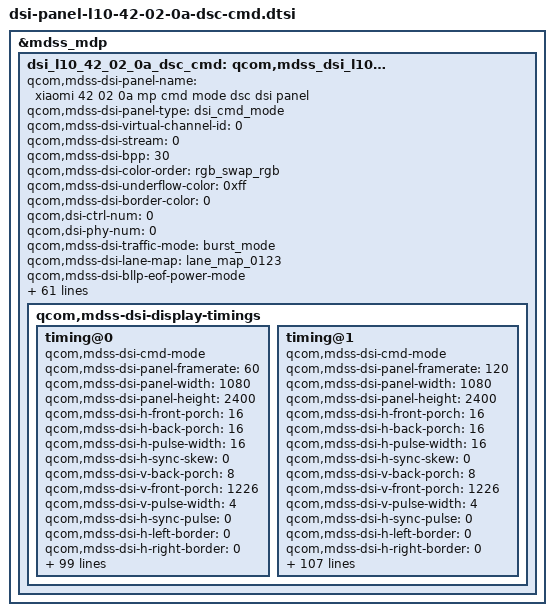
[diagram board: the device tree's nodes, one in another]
&mdss_mdp {
	dsi_l10_42_02_0a_dsc_cmd: qcom,mdss_dsi_l10_42_02_0a_dsc_cmd {
		qcom,mdss-dsi-panel-name = "xiaomi 42 02 0a mp cmd mode dsc dsi panel";
		qcom,mdss-dsi-panel-type = "dsi_cmd_mode";
		qcom,mdss-dsi-virtual-channel-id = <0>;
		qcom,mdss-dsi-stream = <0>;
		qcom,mdss-dsi-bpp = <30>;
		qcom,mdss-dsi-color-order = "rgb_swap_rgb";
		qcom,mdss-dsi-underflow-color = <0xff>;
		qcom,mdss-dsi-border-color = <0>;

		qcom,dsi-ctrl-num = <0>;
		qcom,dsi-phy-num = <0>;

		qcom,mdss-dsi-traffic-mode = "burst_mode";
		qcom,mdss-dsi-lane-map = "lane_map_0123";
		qcom,mdss-dsi-bllp-eof-power-mode;
		qcom,mdss-dsi-bllp-power-mode;
		qcom,mdss-dsi-lane-0-state;
		qcom,mdss-dsi-lane-1-state;
		qcom,mdss-dsi-lane-2-state;
		qcom,mdss-dsi-lane-3-state;
		qcom,mdss-dsi-dma-trigger = "trigger_sw";
		qcom,mdss-dsi-mdp-trigger = "none";
		qcom,mdss-dsi-reset-sequence =  <1 11>, <0 1>, <1 11>;
		qcom,mdss-pan-physical-width-dimension = <695>;
		qcom,mdss-pan-physical-height-dimension = <1545>;
		qcom,mdss-dsi-te-pin-select = <1>;
		qcom,mdss-dsi-wr-mem-start = <0x2c>;
		qcom,mdss-dsi-wr-mem-continue = <0x3c>;
		qcom,mdss-dsi-te-dcs-command = <1>;
		qcom,mdss-dsi-te-check-enable;
		qcom,mdss-dsi-te-using-te-pin;
		qcom,mdss-dsi-tx-eot-append;
		qcom,mdss-dsi-lp11-init;

		qcom,mdss-dsi-bl-inverted-dbv;
		qcom,bl-update-flag = "delay_until_first_frame";
		qcom,mdss-dsi-panel-mode-switch;

		qcom,mdss-dsi-panel-hdr-enabled;
		qcom,mdss-dsi-panel-hdr-color-primaries = <14500 15500 32000 17000 15500 30000 8000 3000>;
		qcom,mdss-dsi-panel-peak-brightness = <4200000>;
		qcom,mdss-dsi-panel-blackness-level = <3230>;
		qcom,mdss-dsi-dma-schedule-line = <1>;
		qcom,mdss-dsi-dma-schedule-window = <10>;

		qcom,mdss-dsi-display-timings {
			/* 60 Hz */
			timing@0{
				qcom,mdss-dsi-cmd-mode;
				qcom,mdss-dsi-panel-framerate = <60>;
				qcom,mdss-dsi-panel-width = <1080>;
				qcom,mdss-dsi-panel-height = <2400>;
				qcom,mdss-dsi-h-front-porch = <16>;
				qcom,mdss-dsi-h-back-porch = <16>;
				qcom,mdss-dsi-h-pulse-width = <16>;
				qcom,mdss-dsi-h-sync-skew = <0>;
				qcom,mdss-dsi-v-back-porch = <8>;
				qcom,mdss-dsi-v-front-porch = <1226>;
				qcom,mdss-dsi-v-pulse-width = <4>;
				qcom,mdss-dsi-h-sync-pulse = <0>;
				qcom,mdss-dsi-h-left-border = <0>;
				qcom,mdss-dsi-h-right-border = <0>;
				qcom,mdss-dsi-v-top-border = <0>;
				qcom,mdss-dsi-v-bottom-border = <0>;
				qcom,mdss-dsi-panel-clockrate = <1100000000>;
				qcom,mdss-dsi-panel-jitter = <0x5 0x1>;
				qcom,mdss-mdp-transfer-time-us = <6800>;
				qcom,mdss-dsi-on-command = [
					/* enter aod with no black */
					39 00 00 00 00 00 05 FF AA 55 A5 80
					15 00 00 00 00 00 02 6F 61
					15 00 00 00 00 00 02 F3 80
					/* VESA ON */
					15 00 00 00 00 00 02 90 01
					/* VESA Edition */
					39 00 00 00 00 00 13 91
						AB 28 00 0C C2 00 03 1C 01 7E 00 0F 08 BB 04 3D
						10 F0
					15 00 00 00 00 00 02 03 01
					15 00 00 00 00 00 02 2C 00
					/* TE ON */
					15 00 00 00 00 00 02 35 00
					/* BACKLIGHT ON */
					15 00 00 00 00 00 02 53 20
					39 00 00 00 00 00 05 51 00 00 00 00
					/* CASET/RASET */
					39 00 00 00 00 00 05 2A 00 00 04 37
					39 00 00 00 00 00 05 2B 00 00 09 5F
					/* 60 Hz */
					15 00 00 00 00 00 02 2F 01
					15 00 00 00 00 00 02 26 01
					/* OSC calibration */
					39 00 00 00 00 00 06 F0 55 AA 52 08 01
					39 00 00 00 00 00 08 C3 9B 01 94 D0 22 02 00
					/* round on */
					39 00 00 00 00 00 06 F0 55 AA 52 08 07
					39 00 00 00 00 00 03 C0 05 02
					/*ESD Error flag  Active high*/
					39 00 00 40 00 00 06 F0 55 AA 52 08 00
					39 00 00 40 00 00 02 6F 05
					39 00 00 00 00 00 02 BE 08
					/* VBP & VFP */
					39 00 00 00 00 00 05 3B 00 14 00 1C
					/* fix cts 120hz failed */
					39 00 00 00 00 00 06 F0 55 AA 52 08 00
					39 00 00 00 00 00 03 BA 01 B1
					39 00 00 00 00 00 02 6F 08
					39 00 00 00 00 00 03 BA 01 B1
					39 00 00 00 00 00 03 BB 01 B1
					/* Sleep Out */
					05 00 00 00 50 00 02 11 00
					/* Display On */
					05 00 00 00 00 00 02 29 00
				];
				qcom,mdss-dsi-off-command = [
					05 00 00 00 00 00 02 28 00
					05 00 00 00 64 00 02 10 00
				];
				qcom,mdss-dsi-on-command-state = "dsi_lp_mode";
				qcom,mdss-dsi-off-command-state = "dsi_lp_mode";

				qcom,mdss-dsi-timing-switch-command = [
					/* 60 Hz */
					39 00 00 40 00 00 02 2F 01
					39 00 00 00 00 00 02 26 01
				];
				qcom,mdss-dsi-timing-switch-command-state = "dsi_hs_mode";
				qcom,mdss-dsi-timing-switch-command-update = <0x26 1 1>;

				qcom,mdss-dsi-nolp-command = [
					39 00 00 00 00 00 06 F0 55 AA 52 08 00
					39 00 00 40 00 00 02 B2 18
					39 00 00 00 00 00 02 65 00
					39 00 00 00 00 00 02 38 00
				];
				qcom,mdss-dsi-nolp-command-state = "dsi_lp_mode";

				qcom,compression-mode = "dsc";
				qcom,mdss-dsc-version = <0x11>;
				qcom,mdss-dsc-scr-version = <0x0>;
				qcom,mdss-dsc-slice-height = <12>;
				qcom,mdss-dsc-slice-width = <1080>;
				qcom,mdss-dsc-slice-per-pkt = <1>;
				qcom,mdss-dsc-bit-per-component = <10>;
				qcom,mdss-dsc-bit-per-pixel = <8>;
				qcom,mdss-dsc-block-prediction-enable;
			};

			/* 120Hz */
			timing@1 {
				qcom,mdss-dsi-cmd-mode;
				qcom,mdss-dsi-panel-framerate = <120>;
				qcom,mdss-dsi-panel-width = <1080>;
				qcom,mdss-dsi-panel-height = <2400>;
				qcom,mdss-dsi-h-front-porch = <16>;
				qcom,mdss-dsi-h-back-porch = <16>;
				qcom,mdss-dsi-h-pulse-width = <16>;
				qcom,mdss-dsi-h-sync-skew = <0>;
				qcom,mdss-dsi-v-back-porch = <8>;
				qcom,mdss-dsi-v-front-porch = <1226>;
				qcom,mdss-dsi-v-pulse-width = <4>;
				qcom,mdss-dsi-h-sync-pulse = <0>;
				qcom,mdss-dsi-h-left-border = <0>;
				qcom,mdss-dsi-h-right-border = <0>;
				qcom,mdss-dsi-v-top-border = <0>;
				qcom,mdss-dsi-v-bottom-border = <0>;
				qcom,mdss-dsi-panel-clockrate = <1100000000>;
				qcom,mdss-dsi-panel-jitter = <0x5 0x1>;
				qcom,mdss-mdp-transfer-time-us = <6800>;
				qcom,mdss-dsi-on-command = [
					/* enter aod with no black */
					39 00 00 00 00 00 05 FF AA 55 A5 80
					15 00 00 00 00 00 02 6F 61
					15 00 00 00 00 00 02 F3 80
					/* VESA ON */
					15 00 00 00 00 00 02 90 01
					/* VESA Edition */
					39 00 00 00 00 00 13 91
						AB 28 00 0C C2 00 03 1C 01 7E 00 0F 08 BB 04 3D
						10 F0
					15 00 00 00 00 00 02 03 01
					15 00 00 00 00 00 02 2C 00
					/* TE ON */
					15 00 00 00 00 00 02 35 00
					/* BACKLIGHT ON */
					15 00 00 00 00 00 02 53 20
					39 00 00 00 00 00 05 51 00 00 00 00
					/* CASET/RASET */
					39 00 00 00 00 00 05 2A 00 00 04 37
					39 00 00 00 00 00 05 2B 00 00 09 5F
					/* 120 Hz */
					39 00 00 00 00 00 06 F0 55 AA 52 08 00
					15 00 00 00 00 00 02 6F 09
					15 00 00 00 00 00 02 C0 20
					15 00 00 00 00 00 02 2F 02
					/* OSC calibration */
					39 00 00 00 00 00 06 F0 55 AA 52 08 01
					39 00 00 00 00 00 08 C3 9B 01 94 D0 22 02 00
					/* round on */
					39 00 00 00 00 00 06 F0 55 AA 52 08 07
					39 00 00 00 00 00 03 C0 05 02
					/*ESD Error flag  Active high*/
					39 00 00 40 00 00 06 F0 55 AA 52 08 00
					39 00 00 40 00 00 02 6F 05
					39 00 00 00 00 00 02 BE 08
					/* fix cts 120hz failed */
					39 00 00 00 00 00 06 F0 55 AA 52 08 00
					39 00 00 00 00 00 03 BA 01 B1
					39 00 00 00 00 00 02 6F 08
					39 00 00 00 00 00 03 BA 01 B1
					39 00 00 00 00 00 03 BB 01 B1
					/* VBP & VFP */
					39 00 00 00 00 00 05 3B 00 14 00 1C
					/* Sleep Out */
					05 00 00 00 50 00 02 11 00
					/* Display On */
					05 00 00 00 00 00 02 29 00
				];

				qcom,mdss-dsi-off-command = [
					05 00 00 00 00 00 02 28 00
					05 00 00 00 64 00 02 10 00
				];
				qcom,mdss-dsi-on-command-state = "dsi_lp_mode";
				qcom,mdss-dsi-off-command-state = "dsi_lp_mode";

				qcom,mdss-dsi-timing-switch-command = [
					/* 120 Hz */
					39 00 00 00 00 00 02 2F 02
					39 00 00 40 00 00 06 F0 55 AA 52 08 00
					39 00 00 40 00 00 02 6F 09
					39 00 00 40 00 00 02 C0 20
					39 00 00 40 00 00 06 F0 55 AA 52 08 02
					39 00 00 40 00 00 02 CC 30
					39 00 00 00 0A 00 02 CE 01
					/*120 Hz  cmd_2*/
					39 00 00 00 00 00 06 F0 55 AA 52 08 02
					39 00 00 00 00 00 02 CC 00
				];
				qcom,mdss-dsi-timing-switch-command-update = <0xC0 3 1>;
				qcom,mdss-dsi-timing-switch-command-state = "dsi_hs_mode";

				qcom,mdss-dsi-nolp-command = [
					39 00 00 00 00 00 06 F0 55 AA 52 08 00
					39 00 00 40 00 00 02 B2 18
					39 00 00 00 00 00 02 65 00
					39 00 00 40 22 00 02 38 00
					/* 120 Hz */
					39 00 00 40 00 00 06 F0 55 AA 52 08 00
					39 00 00 40 00 00 02 6F 09
					39 00 00 40 00 00 02 C0 20
					39 00 00 00 00 00 02 2F 02
				];
				qcom,mdss-dsi-nolp-command-state = "dsi_lp_mode";

				qcom,compression-mode = "dsc";
				qcom,mdss-dsc-version = <0x11>;
				qcom,mdss-dsc-scr-version = <0x0>;
				qcom,mdss-dsc-slice-height = <12>;
				qcom,mdss-dsc-slice-width = <1080>;
				qcom,mdss-dsc-slice-per-pkt = <1>;
				qcom,mdss-dsc-bit-per-component = <10>;
				qcom,mdss-dsc-bit-per-pixel = <8>;
				qcom,mdss-dsc-block-prediction-enable;
			};

		};
	};
};

&dsi_l10_42_02_0a_dsc_cmd {
	mi,panel-id = <0x004C3130 0x00420200>;
	mi,hbm-51-ctl-flag;
	mi,hbm-bl-min-level = <1>;
	mi,hbm-bl-max-level = <2047>;
	mi,panel-on-dimming-delay = <120>;

	/* IRQF_ONESHOT | IRQF_TRIGGER_HIGH */
	mi,esd-err-irq-gpio = <&tlmm 116 0x2004>;
	qcom,esd-check-enabled;
	qcom,esd-aod-check-enabled;
	qcom,mdss-dsi-panel-status-check-mode = "reg_read";
	qcom,mdss-dsi-panel-status-offset-command = [
		39 00 00 00 00 00 05 FF AA 55 A5 81
		15 00 00 00 00 00 02 6F 0F];
	qcom,mdss-dsi-panel-status-command = [
		06 00 00 01 00 00 01 FA
		06 00 00 01 00 00 01 91];
	qcom,mdss-dsi-panel-status-read-length = <1 18>;
	qcom,mdss-dsi-panel-max-error-count = <3>;
	qcom,mdss-dsi-panel-status-value = <0x00>,
			<0xAB 0x28 0x00 0x0C 0xC2 0x00 0x03 0x1C 0x01 0x7E 0x00 0x0F 0x08 0xBB 0x04 0x3D 0x10 0xF0>;
	qcom,mdss-dsi-panel-status-command-state = "dsi_lp_mode";
	qcom,mdss-dsi-panel-status-offset-command-state = "dsi_lp_mode";


	mi,ddic-round-corner-enabled;

	mi,flat-update-flag;
	mi,flat-need-sync-te;

	mi,max-brightness-clone = <4095>;
	mi,mdss-dsi-fac-bl-max-level = <2047>;
	mi,mdss-fac-brightness-max-level = <2047>;
	mi,doze-hbm-dbv-level = <252>;
	mi,doze-lbm-dbv-level = <20>;
	mi,thermal-dimming-flag;

	mi,panel-hbm-backlight-threshold = <2047>;
	mi,panel-count-hbm-by-backlight-flag;

	qcom,mdss-dsi-display-timings {
		timing@0{ /* 60 hz */
			/*<flat on gamma, flat off gamma>*/
			mi,mdss-flat-status-control-gamma-cfg = <0x04 0x01>;

			mi,mdss-dsi-dimmingon-command = [15 00 00 00 00 00 02 53 28];
			mi,mdss-dsi-dimmingon-command-state = "dsi_hs_mode";
			mi,mdss-dsi-dimmingoff-command = [15 00 00 00 00 00 02 53 20];
			mi,mdss-dsi-dimmingoff-command-state = "dsi_hs_mode";

			mi,mdss-dsi-switch-page-command = [
				/* switch page, last byte is page config */
				39 00 00 00 00 00 06 F0 55 AA 52 08 00
			];
			/* <mipi_address  update_index  update_length> */
			mi,mdss-dsi-switch-page-command-update = <0xF0 0 5>;
			mi,mdss-dsi-switch-page-command-state = "dsi_lp_mode";

			mi,mdss-dsi-flat-mode-read-pre-command = [
				39 00 00 00 00 00 06 F0 55 AA 52 08 00
				39 00 00 00 00 00 02 6F 3F
			];
			mi,mdss-dsi-flat-mode-read-pre-command-state = "dsi_lp_mode";

			mi,mdss-dsi-flat-mode-on-command = [
				/* 60 Hz */
				39 00 00 00 00 00 02 2F 01
				39 00 00 60 00 00 02 26 04
				39 00 00 60 00 00 06 F0 55 AA 52 08 08
				39 00 00 60 00 00 02 6F 07
				39 00 00 20 00 00 05 B9 00 00 00 00
			];
			/* <mipi_address  update_index  update_length> */
			mi,mdss-dsi-flat-mode-on-command-update = <0xB9 4 4>;
			mi,mdss-dsi-flat-mode-on-command-state = "dsi_lp_mode";

			mi,mdss-dsi-flat-mode-off-read-pre-command = [
				39 00 00 00 00 00 06 F0 55 AA 52 08 00
				39 00 00 00 00 00 02 6F 48
			];
			mi,mdss-dsi-flat-mode-off-read-pre-command-state = "dsi_lp_mode";

			mi,mdss-dsi-flat-mode-off-command = [
				/* 60 Hz */
				39 00 00 00 00 00 02 2F 01
				39 00 00 60 00 00 02 26 01
				39 00 00 60 00 00 06 F0 55 AA 52 08 08
				39 00 00 60 00 00 02 6F 07
				39 00 00 20 00 00 05 B9 00 00 00 00
			];
			/* <mipi_address  update_index  update_length> */
			mi,mdss-dsi-flat-mode-off-command-update = <0xB9 4 4>;
			mi,mdss-dsi-flat-mode-off-command-state = "dsi_lp_mode";

			mi,mdss-dsi-hbm-on-command = [
				39 00 00 00 00 00 05 51 0F FF 00 00];
			mi,mdss-dsi-hbm-on-command-state = "dsi_lp_mode";
			mi,mdss-dsi-hbm-off-command = [
				39 00 00 00 00 00 05 51 07 FF 00 00];
			mi,mdss-dsi-hbm-off-command-state = "dsi_lp_mode";

			mi,mdss-dsi-doze-hbm-command = [
				/* 60 Hz */
				39 00 00 60 00 00 02 2F 01
				39 00 00 60 00 00 02 26 01
				39 00 00 60 00 00 06 F0 55 AA 52 08 00
				39 00 00 60 00 00 02 B2 08
				39 00 00 60 00 00 05 51 00 00 0F FF
				39 00 00 60 00 00 01 39
				39 00 00 20 00 00 02 65 01
			];
			mi,mdss-dsi-doze-hbm-command-state = "dsi_lp_mode";

			mi,mdss-dsi-doze-lbm-command = [
				/* 60 Hz */
				39 00 00 60 00 00 02 2F 01
				39 00 00 60 00 00 02 26 01
				39 00 00 60 00 00 06 F0 55 AA 52 08 00
				39 00 00 60 00 00 02 B2 08
				39 00 00 60 00 00 05 51 00 00 01 55
				39 00 00 60 00 00 01 39
				39 00 00 20 00 00 02 65 01
			];
			mi,mdss-dsi-doze-lbm-command-state = "dsi_lp_mode";

			mi,mdss-dsi-doze-hbm-nolp-command = [
				39 00 00 00 00 00 06 F0 55 AA 52 08 00
				39 00 00 40 00 00 02 B2 18
				39 00 00 40 00 00 05 51 00 00 0F FF
				39 00 00 00 00 00 02 65 00
				39 00 00 00 07 00 01 38
			];
			mi,mdss-dsi-doze-hbm-nolp-command-state = "dsi_lp_mode";

			mi,mdss-dsi-doze-lbm-nolp-command = [
				39 00 00 00 00 00 06 F0 55 AA 52 08 00
				39 00 00 40 00 00 02 B2 18
				39 00 00 40 00 00 05 51 00 00 0F FF
				39 00 00 00 00 00 02 65 00
				39 00 00 00 07 00 01 38
			];
			mi,mdss-dsi-doze-lbm-nolp-command-state = "dsi_lp_mode";

			mi,mdss-dsi-doze-to-off-command = [
				39 00 00 40 00 00 06 F0 55 AA 52 08 01
				39 00 00 00 00 00 02 CE 0C
				39 00 00 40 00 00 02 28 00
				39 00 00 00 AA 00 02 10 00
			];
			mi,mdss-dsi-doze-to-off-command-state = "dsi_lp_mode";

			mi,mdss-dsi-round-corner-on-command = [
				/* Page 07 */
				39 00 00 00 00 00 06 F0 55 AA 52 08 07
				/* Round on */
				39 00 00 00 00 00 03 C0 05 02
			];
			mi,mdss-dsi-round-corner-on-command-state = "dsi_lp_mode";
			mi,mdss-dsi-round-corner-off-command = [
				/* Page 07 */
				39 00 00 00 00 00 06 F0 55 AA 52 08 07
				/* Round off */
				39 00 00 00 00 00 03 C0 00 02
			];
			mi,mdss-dsi-round-corner-off-command-state = "dsi_lp_mode";
		};

		timing@1{ /* 120 hz */
			/*<flat on gamma, flat off gamma>*/
			mi,mdss-flat-status-control-gamma-cfg = <0x60 0x20>;

			mi,mdss-dsi-dimmingon-command = [15 00 00 00 00 00 02 53 28];
			mi,mdss-dsi-dimmingon-command-state = "dsi_hs_mode";
			mi,mdss-dsi-dimmingoff-command = [15 00 00 00 00 00 02 53 20];
			mi,mdss-dsi-dimmingoff-command-state = "dsi_hs_mode";

			mi,mdss-dsi-hbm-on-command = [
				39 00 00 00 00 00 05 51 0F FF 00 00];
			mi,mdss-dsi-hbm-on-command-state = "dsi_lp_mode";
			mi,mdss-dsi-hbm-off-command = [
				39 00 00 00 00 00 05 51 07 FF 00 00];
			mi,mdss-dsi-hbm-off-command-state = "dsi_lp_mode";

			mi,mdss-dsi-switch-page-command = [
				/* switch page, last byte is page config */
				39 00 00 00 00 00 06 F0 55 AA 52 08 00
			];
			/* <mipi_address  update_index  update_length> */
			mi,mdss-dsi-switch-page-command-update = <0xF0 0 5>;
			mi,mdss-dsi-switch-page-command-state = "dsi_lp_mode";

			mi,mdss-dsi-flat-mode-read-pre-command = [
				39 00 00 00 00 00 06 F0 55 AA 52 08 00
				39 00 00 00 00 00 02 6F 3F
			];
			mi,mdss-dsi-flat-mode-read-pre-command-state = "dsi_lp_mode";

			mi,mdss-dsi-flat-mode-on-command = [
				/* 120 Hz gir cmd_1,need sync te*/
				39 00 00 60 00 00 02 2F 02
				39 00 00 60 00 00 06 F0 55 AA 52 08 00
				39 00 00 60 00 00 02 6F 09
				39 00 00 60 00 00 02 C0 60
				39 00 00 60 00 00 06 F0 55 AA 52 08 02
				39 00 00 60 00 00 02 CC 30
				39 00 00 60 00 00 02 CE 01
				39 00 00 60 00 00 06 F0 55 AA 52 08 08
				39 00 00 60 00 00 02 6F 07
				39 00 00 20 08 00 05 B9 00 00 00 00
			];
			/* <mipi_address  update_index  update_length> */
			mi,mdss-dsi-flat-mode-on-command-update = <0xB9 9 4>;

			mi,mdss-dsi-flat-mode-on-sec-command = [
				/* 120 Hz gir cmd_2*/
				39 00 00 00 00 00 06 F0 55 AA 52 08 02
				39 00 00 00 00 00 02 CC 00
			];
			mi,mdss-dsi-flat-mode-on-command-state = "dsi_hs_mode";
			mi,mdss-dsi-flat-mode-on-sec-command-state = "dsi_lp_mode";

			mi,mdss-dsi-flat-mode-off-read-pre-command = [
				39 00 00 00 00 00 06 F0 55 AA 52 08 00
				39 00 00 00 00 00 02 6F 48
			];
			mi,mdss-dsi-flat-mode-off-read-pre-command-state = "dsi_lp_mode";

			mi,mdss-dsi-flat-mode-off-command = [
				/* 120 Hz gir cmd_1,need sync te*/
				39 00 00 60 00 00 02 2F 02
				39 00 00 60 00 00 06 F0 55 AA 52 08 00
				39 00 00 60 00 00 02 6F 09
				39 00 00 60 00 00 02 C0 20
				39 00 00 60 00 00 06 F0 55 AA 52 08 02
				39 00 00 60 00 00 02 CC 30
				39 00 00 60 00 00 02 CE 01
				39 00 00 60 00 00 06 F0 55 AA 52 08 08
				39 00 00 60 00 00 02 6F 07
				39 00 00 20 08 00 05 B9 00 00 00 00
			];
			/* <mipi_address  update_index  update_length> */
			mi,mdss-dsi-flat-mode-off-command-update = <0xB9 9 4>;

			mi,mdss-dsi-flat-mode-off-sec-command = [
				/* 120 Hz gir cmd_2*/
				39 00 00 00 00 00 06 F0 55 AA 52 08 02
				39 00 00 00 00 00 02 CC 00
			];
			mi,mdss-dsi-flat-mode-off-command-state = "dsi_hs_mode";
			mi,mdss-dsi-flat-mode-off-sec-command-state = "dsi_lp_mode";

			mi,mdss-dsi-doze-hbm-command = [
				/* 60 Hz */
				39 00 00 60 00 00 02 2F 01
				39 00 00 60 00 00 02 26 01
				39 00 00 60 00 00 06 F0 55 AA 52 08 00
				39 00 00 60 00 00 02 B2 08
				39 00 00 60 00 00 05 51 00 00 0F FF
				39 00 00 60 00 00 01 39
				39 00 00 20 00 00 02 65 01
			];
			mi,mdss-dsi-doze-hbm-command-state = "dsi_lp_mode";

			mi,mdss-dsi-doze-lbm-command = [
				/* 60 Hz */
				39 00 00 60 00 00 02 2F 01
				39 00 00 60 00 00 02 26 01
				39 00 00 60 00 00 06 F0 55 AA 52 08 00
				39 00 00 60 00 00 02 B2 08
				39 00 00 60 00 00 05 51 00 00 01 55
				39 00 00 60 00 00 01 39
				39 00 00 20 00 00 02 65 01
			];
			mi,mdss-dsi-doze-lbm-command-state = "dsi_lp_mode";

			mi,mdss-dsi-doze-hbm-nolp-command = [
				39 00 00 00 00 00 06 F0 55 AA 52 08 00
				39 00 00 40 00 00 02 B2 18
				39 00 00 00 00 00 05 51 00 00 0F FF
				39 00 00 00 00 00 02 65 00
				39 00 00 00 07 00 01 38
				/* 120 Hz */
				39 00 00 00 00 00 06 F0 55 AA 52 08 00
				39 00 00 40 00 00 02 6F 09
				39 00 00 40 00 00 02 C0 20
				39 00 00 00 00 00 02 2F 02
			];
			mi,mdss-dsi-doze-hbm-nolp-command-state = "dsi_lp_mode";

			mi,mdss-dsi-doze-lbm-nolp-command = [
				39 00 00 00 00 00 06 F0 55 AA 52 08 00
				39 00 00 40 00 00 02 B2 18
				39 00 00 00 00 00 05 51 00 00 0F FF
				39 00 00 00 00 00 02 65 00
				39 00 00 00 07 00 01 38
				/* 120 Hz */
				39 00 00 00 00 00 06 F0 55 AA 52 08 00
				39 00 00 40 00 00 02 6F 09
				39 00 00 40 00 00 02 C0 20
				39 00 00 00 00 00 02 2F 02
			];
			mi,mdss-dsi-doze-lbm-nolp-command-state = "dsi_lp_mode";

			mi,mdss-dsi-doze-to-off-command = [
				39 00 00 40 00 00 06 F0 55 AA 52 08 01
				39 00 00 00 00 00 02 CE 0C
				39 00 00 40 00 00 02 28 00
				39 00 00 00 AA 00 02 10 00
			];
			mi,mdss-dsi-doze-to-off-command-state = "dsi_lp_mode";

			mi,mdss-dsi-round-corner-on-command = [
				/* Page 07 */
				39 00 00 00 00 00 06 F0 55 AA 52 08 07
				/* Round on */
				39 00 00 00 00 00 03 C0 05 02
			];
			mi,mdss-dsi-round-corner-on-command-state = "dsi_lp_mode";
			mi,mdss-dsi-round-corner-off-command = [
				/* Page 07 */
				39 00 00 00 00 00 06 F0 55 AA 52 08 07
				/* Round off */
				39 00 00 00 00 00 03 C0 00 02
			];
			mi,mdss-dsi-round-corner-off-command-state = "dsi_lp_mode";
		};

	};
};

